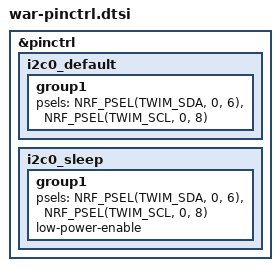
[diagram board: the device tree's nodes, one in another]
// This file was generated from a template. Edit it to match your keyboard.
// See https://docs.zephyrproject.org/4.1.0/hardware/porting/board_porting.html
// and https://docs.zephyrproject.org/4.1.0/hardware/pinctrl/index.html for
// more instructions.

#include <dt-bindings/pinctrl/nrf-pinctrl.h>

&pinctrl {
    i2c0_default: i2c0_default {
        group1 {
            psels = <NRF_PSEL(TWIM_SDA, 0, 6)>,
                    <NRF_PSEL(TWIM_SCL, 0, 8)>;
        };
    };

    i2c0_sleep: i2c0_sleep {
        group1 {
            psels = <NRF_PSEL(TWIM_SDA, 0, 6)>,
                    <NRF_PSEL(TWIM_SCL, 0, 8)>;
            low-power-enable;
        };
    };
};
